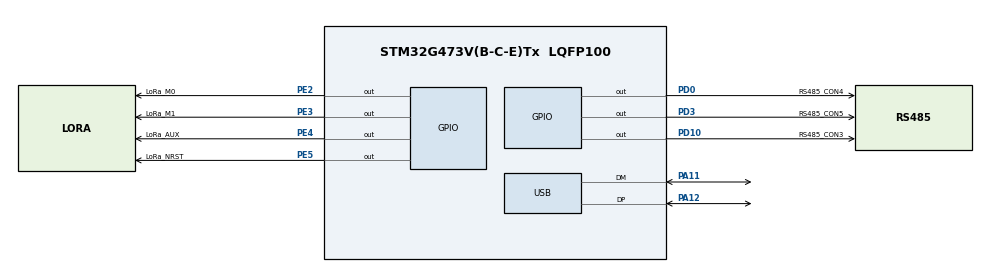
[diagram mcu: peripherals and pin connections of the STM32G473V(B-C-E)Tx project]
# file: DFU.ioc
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Mcu.Family=STM32G4
Mcu.Name=STM32G473V(B-C-E)Tx
Mcu.Package=LQFP100
NVIC.PriorityGroup=NVIC_PRIORITYGROUP_4
NVIC.USB_LP_IRQn=true\:0\:0\:false\:false\:true\:false\:true\:true
PA10.Signal=USART1_RX
PA11.Mode=Device
PA11.Signal=USB_DM
PA12.Mode=Device
PA12.Signal=USB_DP
PA13.Mode=Serial_Wire
PA13.Signal=SYS_JTMS-SWDIO
PA14.Mode=Serial_Wire
PA14.Signal=SYS_JTCK-SWCLK
PA15.Signal=I2C1_SCL
PA2.Signal=QUADSPI1_BK1_NCS
PA3.Signal=QUADSPI1_CLK
PA9.Signal=USART1_TX
PB0.Signal=QUADSPI1_BK1_IO1
PB13.Signal=SPI2_SCK
PC14-OSC32_IN.Mode=LSE-External-Oscillator
PC14-OSC32_IN.Signal=RCC_OSC32_IN
PC15-OSC32_OUT.Mode=LSE-External-Oscillator
PC15-OSC32_OUT.Signal=RCC_OSC32_OUT
PD0.GPIO_Label=RS485_CON4
PD0.Signal=GPIO_Output
PD10.GPIO_Label=RS485_CON3
PD10.Signal=GPIO_Output
PD3.GPIO_Label=RS485_CON5
PD3.Signal=GPIO_Output
PD5.Signal=USART2_TX
PD6.Signal=USART2_RX
PD8.Signal=USART3_TX
PD9.Signal=USART3_RX
PE2.GPIO_Label=LoRa_M0
PE2.Signal=GPIO_Output
PE3.GPIO_Label=LoRa_M1
PE3.Signal=GPIO_Output
PE4.GPIO_Label=LoRa_AUX
PE4.Signal=GPIO_Output
PE5.GPIO_Label=LoRa_NRST
PE5.Signal=GPIO_Output
PF0-OSC_IN.Mode=HSE-External-Oscillator
PF0-OSC_IN.Signal=RCC_OSC_IN
PF1-OSC_OUT.Mode=HSE-External-Oscillator
PF1-OSC_OUT.Signal=RCC_OSC_OUT
ProjectManager.HeapSize=0x200
ProjectManager.StackSize=0x400
ProjectManager.TargetToolchain=MDK-ARM V5.32
RCC.ADC12Freq_Value=170000000
RCC.ADC345Freq_Value=170000000
RCC.AHBFreq_Value=170000000
RCC.APB1Freq_Value=170000000
RCC.APB1TimFreq_Value=170000000
RCC.APB2Freq_Value=170000000
RCC.APB2TimFreq_Value=170000000
RCC.CK48CLockSelection=RCC_USBCLKSOURCE_HSI48
RCC.CortexFreq_Value=170000000
RCC.EXTERNAL_CLOCK_VALUE=12288000
RCC.HCLKFreq_Value=170000000
RCC.HSE_VALUE=8000000
RCC.HSI48_VALUE=48000000
RCC.HSI_VALUE=16000000
RCC.PLLM=RCC_PLLM_DIV2
RCC.PLLN=85
RCC.PLLQ=RCC_PLLQ_DIV4
RCC.PLLSourceVirtual=RCC_PLLSOURCE_HSE
RCC.RTCClockSelection=RCC_RTCCLKSOURCE_LSE
RCC.SYSCLKFreq_VALUE=170000000
RCC.SYSCLKSource=RCC_SYSCLKSOURCE_PLLCLK
RCC.USBFreq_Value=48000000
RCC.VCOOutputFreq_Value=340000000
USB.Sof_enable=ENABLE
USB_DEVICE.CLASS_NAME_FS=DFU
USB_DEVICE.USBD_LPM_ENABLED=1
USB_DEVICE.VirtualMode=Dfu
USB_DEVICE.VirtualModeFS=Dfu_FS
VP_SYS_VS_DBSignals.Mode=DisableDeadBatterySignals
VP_USB_DEVICE_VS_USB_DEVICE_DFU_FS.Mode=DFU_FS
board=custom

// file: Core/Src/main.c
/* USER CODE BEGIN Header */
/**
 ******************************************************************************
 * @file           : main.c
 * @brief          : Main program body
 ******************************************************************************
 * @attention
 *
 * Copyright (c) 2024 STMicroelectronics.
 * All rights reserved.
 *
 * This software is licensed under terms that can be found in the LICENSE file
 * in the root directory of this software component.
 * If no LICENSE file comes with this software, it is provided AS-IS.
 *
 ******************************************************************************
 */
/* USER CODE END Header */
#include "main.h"
#include "usb_device.h"
#include "gpio.h"

void SystemClock_Config(void);
/* USER CODE BEGIN PFP */
#include "usbd_cdc_if.h"

/* USER CODE END PFP */

int main(void)
{

    /* MCU Configuration--------------------------------------------------------*/

    /* Reset of all peripherals, Initializes the Flash interface and the Systick. */
    HAL_Init();

    /* Configure the system clock */
    SystemClock_Config();

    /* Initialize all configured peripherals */
    MX_GPIO_Init();
    MX_USB_Device_Init();

    /* Infinite loop */
    while (1) {

        /* USER CODE BEGIN 3 */
        char data[] = "Hello World\n";
        CDC_Transmit_FS((uint8_t *)data, strlen(data));

        HAL_Delay(1000);
    }
    /* USER CODE END 3 */
}

void SystemClock_Config(void)
{
    LL_FLASH_SetLatency(LL_FLASH_LATENCY_4);
    while (LL_FLASH_GetLatency() != LL_FLASH_LATENCY_4) {
    }
    LL_PWR_EnableRange1BoostMode();
    LL_RCC_HSE_Enable();
    /* Wait till HSE is ready */
    while (LL_RCC_HSE_IsReady() != 1) {
    }

    LL_RCC_HSI48_Enable();
    /* Wait till HSI48 is ready */
    while (LL_RCC_HSI48_IsReady() != 1) {
    }

    LL_RCC_PLL_ConfigDomain_SYS(LL_RCC_PLLSOURCE_HSE, LL_RCC_PLLM_DIV_2, 85, LL_RCC_PLLR_DIV_2);
    LL_RCC_PLL_EnableDomain_SYS();
    LL_RCC_PLL_Enable();
    /* Wait till PLL is ready */
    while (LL_RCC_PLL_IsReady() != 1) {
    }

    LL_RCC_SetSysClkSource(LL_RCC_SYS_CLKSOURCE_PLL);
    LL_RCC_SetAHBPrescaler(LL_RCC_SYSCLK_DIV_2);
    /* Wait till System clock is ready */
    while (LL_RCC_GetSysClkSource() != LL_RCC_SYS_CLKSOURCE_STATUS_PLL) {
    }

    /* Insure 1us transition state at intermediate medium speed clock*/
    for (__IO uint32_t i = (170 >> 1); i != 0; i--);

    /* Set AHB prescaler*/
    LL_RCC_SetAHBPrescaler(LL_RCC_SYSCLK_DIV_1);
    LL_RCC_SetAPB1Prescaler(LL_RCC_APB1_DIV_1);
    LL_RCC_SetAPB2Prescaler(LL_RCC_APB2_DIV_1);
    LL_SetSystemCoreClock(170000000);

    /* Update the time base */
    if (HAL_InitTick(TICK_INT_PRIORITY) != HAL_OK) {
        Error_Handler();
    }
}

void Error_Handler(void)
{
    __disable_irq();
    while (1) {
    }
}
